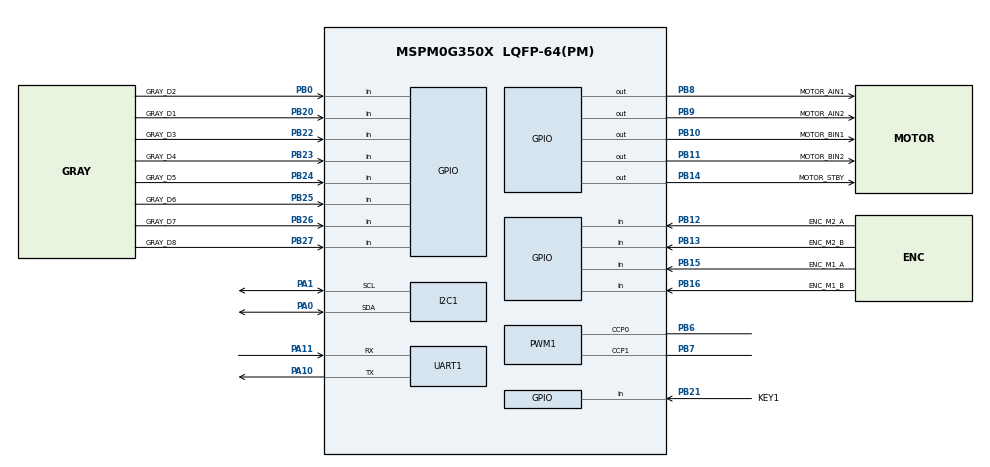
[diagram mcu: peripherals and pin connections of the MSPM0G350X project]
/**
 * @cliArgs --device "MSPM0G350X" --part "Default" --package "LQFP-64(PM)" --product "mspm0_sdk@2.02.00.05"
 * @versions {"tool":"1.21.1+3772"}
 */

/**
 * Import the modules used in this configuration.
 */
const GPIO    = scripting.addModule("/ti/driverlib/GPIO", {}, false);
const GPIO1   = GPIO.addInstance();
const I2C     = scripting.addModule("/ti/driverlib/I2C", {}, false);
const I2C1    = I2C.addInstance();
const PWM     = scripting.addModule("/ti/driverlib/PWM", {}, false);
const PWM1    = PWM.addInstance();
const SYSCTL  = scripting.addModule("/ti/driverlib/SYSCTL");
const SYSTICK = scripting.addModule("/ti/driverlib/SYSTICK");
const UART    = scripting.addModule("/ti/driverlib/UART", {}, false);
const UART1   = UART.addInstance();

/**
 * Write custom configuration values to the imported modules.
 */
const divider9       = system.clockTree["UDIV"];
divider9.divideValue = 2;

const gate7  = system.clockTree["MFCLKGATE"];
gate7.enable = true;

const gate8  = system.clockTree["MFPCLKGATE"];
gate8.enable = true;

const multiplier2         = system.clockTree["PLL_QDIV"];
multiplier2.multiplyValue = 4;

const mux4       = system.clockTree["EXHFMUX"];
mux4.inputSelect = "EXHFMUX_XTAL";

const mux8       = system.clockTree["HSCLKMUX"];
mux8.inputSelect = "HSCLKMUX_SYSPLL0";

const mux12       = system.clockTree["SYSPLLMUX"];
mux12.inputSelect = "zSYSPLLMUX_HFCLK";

const pinFunction4        = system.clockTree["HFXT"];
pinFunction4.inputFreq    = 40;
pinFunction4.enable       = true;
pinFunction4.HFCLKMonitor = true;
pinFunction4.HFXTStartup  = 100;

GPIO1.$name                               = "BOARD_GPIO";
GPIO1.associatedPins.create(18);
GPIO1.associatedPins[0].$name             = "KEY1";
GPIO1.associatedPins[0].direction         = "INPUT";
GPIO1.associatedPins[0].internalResistor  = "PULL_UP";
GPIO1.associatedPins[0].assignedPort      = "PORTB";
GPIO1.associatedPins[0].assignedPin       = "21";
GPIO1.associatedPins[0].pin.$assign       = "PB21";
GPIO1.associatedPins[1].$name             = "MOTOR_AIN1";
GPIO1.associatedPins[1].assignedPort      = "PORTB";
GPIO1.associatedPins[1].assignedPin       = "8";
GPIO1.associatedPins[1].pin.$assign       = "PB8";
GPIO1.associatedPins[2].$name             = "MOTOR_AIN2";
GPIO1.associatedPins[2].assignedPort      = "PORTB";
GPIO1.associatedPins[2].assignedPin       = "9";
GPIO1.associatedPins[2].pin.$assign       = "PB9";
GPIO1.associatedPins[3].$name             = "MOTOR_BIN1";
GPIO1.associatedPins[3].assignedPort      = "PORTB";
GPIO1.associatedPins[3].assignedPin       = "10";
GPIO1.associatedPins[3].pin.$assign       = "PB10";
GPIO1.associatedPins[4].$name             = "MOTOR_BIN2";
GPIO1.associatedPins[4].assignedPort      = "PORTB";
GPIO1.associatedPins[4].assignedPin       = "11";
GPIO1.associatedPins[4].pin.$assign       = "PB11";
GPIO1.associatedPins[5].$name             = "MOTOR_STBY";
GPIO1.associatedPins[5].assignedPort      = "PORTB";
GPIO1.associatedPins[5].assignedPin       = "14";
GPIO1.associatedPins[5].pin.$assign       = "PB14";
GPIO1.associatedPins[6].$name             = "ENC_M1_A";
GPIO1.associatedPins[6].direction         = "INPUT";
GPIO1.associatedPins[6].internalResistor  = "PULL_UP";
GPIO1.associatedPins[6].interruptEn       = true;
GPIO1.associatedPins[6].polarity          = "RISE_FALL";
GPIO1.associatedPins[6].assignedPort      = "PORTB";
GPIO1.associatedPins[6].assignedPin       = "15";
GPIO1.associatedPins[6].pin.$assign       = "PB15";
GPIO1.associatedPins[7].$name             = "ENC_M1_B";
GPIO1.associatedPins[7].direction         = "INPUT";
GPIO1.associatedPins[7].internalResistor  = "PULL_UP";
GPIO1.associatedPins[7].interruptEn       = true;
GPIO1.associatedPins[7].polarity          = "RISE_FALL";
GPIO1.associatedPins[7].assignedPort      = "PORTB";
GPIO1.associatedPins[7].assignedPin       = "16";
GPIO1.associatedPins[7].pin.$assign       = "PB16";
GPIO1.associatedPins[8].$name             = "ENC_M2_A";
GPIO1.associatedPins[8].direction         = "INPUT";
GPIO1.associatedPins[8].internalResistor  = "PULL_UP";
GPIO1.associatedPins[8].interruptEn       = true;
GPIO1.associatedPins[8].polarity          = "RISE_FALL";
GPIO1.associatedPins[8].assignedPort      = "PORTB";
GPIO1.associatedPins[8].assignedPin       = "12";
GPIO1.associatedPins[8].pin.$assign       = "PB12";
GPIO1.associatedPins[9].$name             = "ENC_M2_B";
GPIO1.associatedPins[9].direction         = "INPUT";
GPIO1.associatedPins[9].internalResistor  = "PULL_UP";
GPIO1.associatedPins[9].interruptEn       = true;
GPIO1.associatedPins[9].polarity          = "RISE_FALL";
GPIO1.associatedPins[9].assignedPort      = "PORTB";
GPIO1.associatedPins[9].assignedPin       = "13";
GPIO1.associatedPins[9].pin.$assign       = "PB13";
GPIO1.associatedPins[10].$name            = "GRAY_D1";
GPIO1.associatedPins[10].direction        = "INPUT";
GPIO1.associatedPins[10].internalResistor = "PULL_UP";
GPIO1.associatedPins[10].assignedPort     = "PORTB";
GPIO1.associatedPins[10].assignedPin      = "20";
GPIO1.associatedPins[10].pin.$assign      = "PB20";
GPIO1.associatedPins[11].$name            = "GRAY_D2";
GPIO1.associatedPins[11].direction        = "INPUT";
GPIO1.associatedPins[11].internalResistor = "PULL_UP";
GPIO1.associatedPins[11].assignedPort     = "PORTB";
GPIO1.associatedPins[11].assignedPin      = "0";
GPIO1.associatedPins[11].pin.$assign      = "PB0";
GPIO1.associatedPins[12].$name            = "GRAY_D3";
GPIO1.associatedPins[12].direction        = "INPUT";
GPIO1.associatedPins[12].internalResistor = "PULL_UP";
GPIO1.associatedPins[12].assignedPort     = "PORTB";
GPIO1.associatedPins[12].assignedPin      = "22";
GPIO1.associatedPins[12].pin.$assign      = "PB22";
GPIO1.associatedPins[13].$name            = "GRAY_D4";
GPIO1.associatedPins[13].direction        = "INPUT";
GPIO1.associatedPins[13].internalResistor = "PULL_UP";
GPIO1.associatedPins[13].assignedPort     = "PORTB";
GPIO1.associatedPins[13].assignedPin      = "23";
GPIO1.associatedPins[13].pin.$assign      = "PB23";
GPIO1.associatedPins[14].$name            = "GRAY_D5";
GPIO1.associatedPins[14].direction        = "INPUT";
GPIO1.associatedPins[14].internalResistor = "PULL_UP";
GPIO1.associatedPins[14].assignedPort     = "PORTB";
GPIO1.associatedPins[14].assignedPin      = "24";
GPIO1.associatedPins[14].pin.$assign      = "PB24";
GPIO1.associatedPins[15].$name            = "GRAY_D6";
GPIO1.associatedPins[15].direction        = "INPUT";
GPIO1.associatedPins[15].internalResistor = "PULL_UP";
GPIO1.associatedPins[15].assignedPort     = "PORTB";
GPIO1.associatedPins[15].assignedPin      = "25";
GPIO1.associatedPins[15].pin.$assign      = "PB25";
GPIO1.associatedPins[16].$name            = "GRAY_D7";
GPIO1.associatedPins[16].direction        = "INPUT";
GPIO1.associatedPins[16].internalResistor = "PULL_UP";
GPIO1.associatedPins[16].assignedPort     = "PORTB";
GPIO1.associatedPins[16].assignedPin      = "26";
GPIO1.associatedPins[16].pin.$assign      = "PB26";
GPIO1.associatedPins[17].$name            = "GRAY_D8";
GPIO1.associatedPins[17].direction        = "INPUT";
GPIO1.associatedPins[17].internalResistor = "PULL_UP";
GPIO1.associatedPins[17].assignedPort     = "PORTB";
GPIO1.associatedPins[17].assignedPin      = "27";
GPIO1.associatedPins[17].pin.$assign      = "PB27";

const Board = scripting.addModule("/ti/driverlib/Board", {}, false);

I2C1.$name                             = "I2C_JY901P";
I2C1.basicEnableController             = true;
I2C1.basicControllerBusSpeed           = 100000;
I2C1.advControllerTXFIFOTRIG           = "BYTES_1";
I2C1.advAnalogGlitchFilter             = "DISABLED";
I2C1.intController                     = ["ARBITRATION_LOST","NACK","RXFIFO_TRIGGER","RX_DONE","TX_DONE"];
I2C1.peripheral.$assign                = "I2C0";
I2C1.peripheral.sdaPin.$assign         = "PA0";
I2C1.peripheral.sclPin.$assign         = "PA1";
I2C1.sdaPinConfig.$name                = "ti_driverlib_gpio_GPIOPinGeneric0";
I2C1.sdaPinConfig.hideOutputInversion  = scripting.forceWrite(false);
I2C1.sdaPinConfig.onlyInternalResistor = scripting.forceWrite(false);
I2C1.sdaPinConfig.passedPeripheralType = scripting.forceWrite("Digital");
I2C1.sclPinConfig.$name                = "ti_driverlib_gpio_GPIOPinGeneric1";
I2C1.sclPinConfig.hideOutputInversion  = scripting.forceWrite(false);
I2C1.sclPinConfig.onlyInternalResistor = scripting.forceWrite(false);
I2C1.sclPinConfig.passedPeripheralType = scripting.forceWrite("Digital");

PWM1.$name                              = "MOTOR_PWM";
PWM1.timerCount                         = 1600;
PWM1.peripheral.$assign                 = "TIMG8";
PWM1.peripheral.ccp0Pin.$assign         = "PB6";
PWM1.peripheral.ccp1Pin.$assign         = "PB7";
PWM1.PWM_CHANNEL_0.$name                = "MOTOR_PWM_PWMB";
PWM1.PWM_CHANNEL_1.$name                = "MOTOR_PWM_PWMA";
PWM1.ccp0PinConfig.$name                = "ti_driverlib_gpio_GPIOPinGeneric2";
PWM1.ccp0PinConfig.direction            = scripting.forceWrite("OUTPUT");
PWM1.ccp0PinConfig.hideOutputInversion  = scripting.forceWrite(false);
PWM1.ccp0PinConfig.onlyInternalResistor = scripting.forceWrite(false);
PWM1.ccp0PinConfig.passedPeripheralType = scripting.forceWrite("Digital");
PWM1.ccp1PinConfig.$name                = "ti_driverlib_gpio_GPIOPinGeneric3";
PWM1.ccp1PinConfig.direction            = scripting.forceWrite("OUTPUT");
PWM1.ccp1PinConfig.hideOutputInversion  = scripting.forceWrite(false);
PWM1.ccp1PinConfig.onlyInternalResistor = scripting.forceWrite(false);
PWM1.ccp1PinConfig.passedPeripheralType = scripting.forceWrite("Digital");

SYSCTL.forceDefaultClkConfig = true;
SYSCTL.clockTreeEn           = true;

SYSTICK.periodEnable      = true;
SYSTICK.interruptEnable   = true;
SYSTICK.systickEnable     = true;
SYSTICK.period            = 80000;
SYSTICK.interruptPriority = "0";

UART1.$name                             = "UART_DEBUG";
UART1.targetBaudRate                    = 115200;
UART1.enableFIFO                        = true;
UART1.rxFifoThreshold                   = "DL_UART_RX_FIFO_LEVEL_ONE_ENTRY";
UART1.rxTimeoutValue                    = 15;
UART1.enabledInterrupts                 = ["BREAK_ERROR","DMA_DONE_RX","FRAMING_ERROR","NOISE_ERROR","OVERRUN_ERROR","PARITY_ERROR","RX_TIMEOUT_ERROR","TX"];
UART1.enabledDMARXTriggers              = "DL_UART_DMA_INTERRUPT_RX";
UART1.peripheral.$assign                = "UART0";
UART1.peripheral.rxPin.$assign          = "PA11";
UART1.peripheral.txPin.$assign          = "PA10";
UART1.txPinConfig.$name                 = "ti_driverlib_gpio_GPIOPinGeneric4";
UART1.txPinConfig.direction             = scripting.forceWrite("OUTPUT");
UART1.txPinConfig.hideOutputInversion   = scripting.forceWrite(false);
UART1.txPinConfig.onlyInternalResistor  = scripting.forceWrite(false);
UART1.txPinConfig.passedPeripheralType  = scripting.forceWrite("Digital");
UART1.rxPinConfig.$name                 = "ti_driverlib_gpio_GPIOPinGeneric5";
UART1.rxPinConfig.hideOutputInversion   = scripting.forceWrite(false);
UART1.rxPinConfig.onlyInternalResistor  = scripting.forceWrite(false);
UART1.rxPinConfig.passedPeripheralType  = scripting.forceWrite("Digital");
UART1.DMA_CHANNEL_RX.$name              = "DMA_CH0";
UART1.DMA_CHANNEL_RX.addressMode        = "f2b";
UART1.DMA_CHANNEL_RX.srcLength          = "BYTE";
UART1.DMA_CHANNEL_RX.dstLength          = "BYTE";
UART1.DMA_CHANNEL_RX.peripheral.$assign = "DMA_CH0";

/**
 * Pinmux solution for unlocked pins/peripherals. This ensures that minor changes to the automatic solver in a future
 * version of the tool will not impact the pinmux you originally saw.  These lines can be completely deleted in order to
 * re-solve from scratch.
 */
pinFunction4.peripheral.$suggestSolution           = "SYSCTL";
pinFunction4.peripheral.hfxInPin.$suggestSolution  = "PA5";
pinFunction4.peripheral.hfxOutPin.$suggestSolution = "PA6";
Board.peripheral.$suggestSolution                  = "DEBUGSS";
Board.peripheral.swclkPin.$suggestSolution         = "PA20";
Board.peripheral.swdioPin.$suggestSolution         = "PA19";
